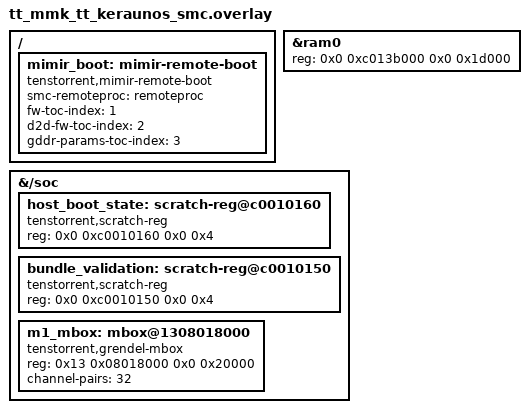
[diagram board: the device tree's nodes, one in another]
/*
 * Copyright (c) 2026 Tenstorrent AI ULC
 *
 * SPDX-License-Identifier: Apache-2.0
 */

/* BL1 starts 128KB from the end of ram0; text+data fit in the first 64KB ,
 * bss/noinit spill into the adjacent memory that BL0P5 occupied (safe to reuse).
 * The window stops short of vuart_ram so the console buffer is left alone.
 */
&ram0 {
	reg = <0x0 0xc013b000 0x0 0x1d000>;
};

/ {
	mimir_boot: mimir-remote-boot {
		compatible = "tenstorrent,mimir-remote-boot";
		smc-remoteproc = <&remoteproc>;
		fw-toc-index = <1>;
		d2d-fw-toc-index = <2>;
		gddr-params-toc-index = <3>;
	};
};

&{/soc} {
	host_boot_state: scratch-reg@c0010160 {
		/* SCRATCH[12] */
		compatible = "tenstorrent,scratch-reg";
		reg = <0x0 0xc0010160 0x0 0x4>;
		status = "okay";
	};

	bundle_validation: scratch-reg@c0010150 {
		/* SCRATCH[10] */
		compatible = "tenstorrent,scratch-reg";
		reg = <0x0 0xc0010150 0x0 0x4>;
		status = "okay";
	};

	m1_mbox: mbox@1308018000 {
		compatible = "tenstorrent,grendel-mbox";
		reg = <0x13 0x08018000 0x0 0x20000>;
		channel-pairs = <32>;
		#mbox-cells = <1>;
	};
};
